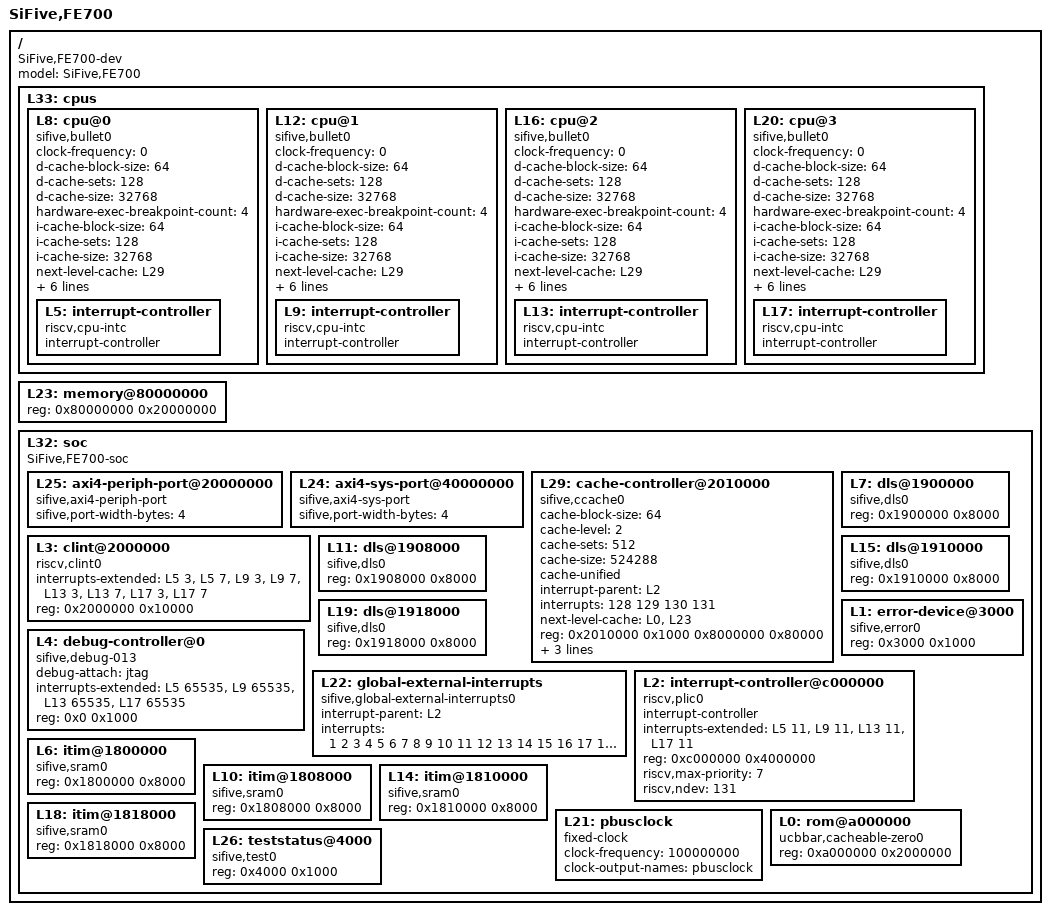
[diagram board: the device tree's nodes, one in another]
/dts-v1/;

/ {
	#address-cells = <1>;
	#size-cells = <1>;
	compatible = "SiFive,FE700-dev", "fe700-dev", "sifive-dev";
	model = "SiFive,FE700";
	L33: cpus {
		#address-cells = <1>;
		#size-cells = <0>;
		L8: cpu@0 {
			clock-frequency = <0>;
			compatible = "sifive,bullet0", "riscv";
			d-cache-block-size = <64>;
			d-cache-sets = <128>;
			d-cache-size = <32768>;
			device_type = "cpu";
			hardware-exec-breakpoint-count = <4>;
			i-cache-block-size = <64>;
			i-cache-sets = <128>;
			i-cache-size = <32768>;
			next-level-cache = <&L29>;
			reg = <0x0>;
			riscv,isa = "rv32imafc";
			riscv,pmpregions = <8>;
			sifive,dls = <&L7>;
			sifive,itim = <&L6>;
			status = "okay";
			timebase-frequency = <1000000>;
			L5: interrupt-controller {
				#interrupt-cells = <1>;
				compatible = "riscv,cpu-intc";
				interrupt-controller;
			};
		};
		L12: cpu@1 {
			clock-frequency = <0>;
			compatible = "sifive,bullet0", "riscv";
			d-cache-block-size = <64>;
			d-cache-sets = <128>;
			d-cache-size = <32768>;
			device_type = "cpu";
			hardware-exec-breakpoint-count = <4>;
			i-cache-block-size = <64>;
			i-cache-sets = <128>;
			i-cache-size = <32768>;
			next-level-cache = <&L29>;
			reg = <0x1>;
			riscv,isa = "rv32imafc";
			riscv,pmpregions = <8>;
			sifive,dls = <&L11>;
			sifive,itim = <&L10>;
			status = "okay";
			timebase-frequency = <1000000>;
			L9: interrupt-controller {
				#interrupt-cells = <1>;
				compatible = "riscv,cpu-intc";
				interrupt-controller;
			};
		};
		L16: cpu@2 {
			clock-frequency = <0>;
			compatible = "sifive,bullet0", "riscv";
			d-cache-block-size = <64>;
			d-cache-sets = <128>;
			d-cache-size = <32768>;
			device_type = "cpu";
			hardware-exec-breakpoint-count = <4>;
			i-cache-block-size = <64>;
			i-cache-sets = <128>;
			i-cache-size = <32768>;
			next-level-cache = <&L29>;
			reg = <0x2>;
			riscv,isa = "rv32imafc";
			riscv,pmpregions = <8>;
			sifive,dls = <&L15>;
			sifive,itim = <&L14>;
			status = "okay";
			timebase-frequency = <1000000>;
			L13: interrupt-controller {
				#interrupt-cells = <1>;
				compatible = "riscv,cpu-intc";
				interrupt-controller;
			};
		};
		L20: cpu@3 {
			clock-frequency = <0>;
			compatible = "sifive,bullet0", "riscv";
			d-cache-block-size = <64>;
			d-cache-sets = <128>;
			d-cache-size = <32768>;
			device_type = "cpu";
			hardware-exec-breakpoint-count = <4>;
			i-cache-block-size = <64>;
			i-cache-sets = <128>;
			i-cache-size = <32768>;
			next-level-cache = <&L29>;
			reg = <0x3>;
			riscv,isa = "rv32imafc";
			riscv,pmpregions = <8>;
			sifive,dls = <&L19>;
			sifive,itim = <&L18>;
			status = "okay";
			timebase-frequency = <1000000>;
			L17: interrupt-controller {
				#interrupt-cells = <1>;
				compatible = "riscv,cpu-intc";
				interrupt-controller;
			};
		};
	};
	L23: memory@80000000 {
		device_type = "memory";
		reg = <0x80000000 0x20000000>;
	};
	L32: soc {
		#address-cells = <1>;
		#size-cells = <1>;
		compatible = "SiFive,FE700-soc", "fe700-soc", "sifive-soc", "simple-bus";
		ranges;
		L25: axi4-periph-port@20000000 {
			#address-cells = <1>;
			#size-cells = <1>;
			compatible = "sifive,axi4-periph-port", "sifive,axi4-port", "sifive,periph-port", "simple-external-bus", "simple-bus";
			ranges = <0x20000000 0x20000000 0x20000000>;
			sifive,port-width-bytes = <4>;
		};
		L24: axi4-sys-port@40000000 {
			#address-cells = <1>;
			#size-cells = <1>;
			compatible = "sifive,axi4-sys-port", "sifive,axi4-port", "sifive,sys-port", "simple-external-bus", "simple-bus";
			ranges = <0x40000000 0x40000000 0x20000000>;
			sifive,port-width-bytes = <4>;
		};
		L29: cache-controller@2010000 {
			cache-block-size = <64>;
			cache-level = <2>;
			cache-sets = <512>;
			cache-size = <524288>;
			cache-unified;
			compatible = "sifive,ccache0", "cache";
			interrupt-parent = <&L2>;
			interrupts = <128 129 130 131>;
			next-level-cache = <&L0 &L23>;
			reg = <0x2010000 0x1000 0x8000000 0x80000>;
			reg-names = "control", "sideband";
			sifive,a-mshr-count = <6>;
			sifive,bank-count = <2>;
			sifive,ecc-granularity = <4>;
		};
		L3: clint@2000000 {
			compatible = "riscv,clint0";
			interrupts-extended = <&L5 3 &L5 7 &L9 3 &L9 7 &L13 3 &L13 7 &L17 3 &L17 7>;
			reg = <0x2000000 0x10000>;
			reg-names = "control";
		};
		L4: debug-controller@0 {
			compatible = "sifive,debug-013", "riscv,debug-013";
			debug-attach = "jtag";
			interrupts-extended = <&L5 65535 &L9 65535 &L13 65535 &L17 65535>;
			reg = <0x0 0x1000>;
			reg-names = "control";
		};
		L7: dls@1900000 {
			compatible = "sifive,dls0";
			reg = <0x1900000 0x8000>;
			reg-names = "mem";
		};
		L11: dls@1908000 {
			compatible = "sifive,dls0";
			reg = <0x1908000 0x8000>;
			reg-names = "mem";
		};
		L15: dls@1910000 {
			compatible = "sifive,dls0";
			reg = <0x1910000 0x8000>;
			reg-names = "mem";
		};
		L19: dls@1918000 {
			compatible = "sifive,dls0";
			reg = <0x1918000 0x8000>;
			reg-names = "mem";
		};
		L1: error-device@3000 {
			compatible = "sifive,error0";
			reg = <0x3000 0x1000>;
		};
		L22: global-external-interrupts {
			compatible = "sifive,global-external-interrupts0";
			interrupt-parent = <&L2>;
			interrupts = <1 2 3 4 5 6 7 8 9 10 11 12 13 14 15 16 17 18 19 20 21 22 23 24 25 26 27 28 29 30 31 32 33 34 35 36 37 38 39 40 41 42 43 44 45 46 47 48 49 50 51 52 53 54 55 56 57 58 59 60 61 62 63 64 65 66 67 68 69 70 71 72 73 74 75 76 77 78 79 80 81 82 83 84 85 86 87 88 89 90 91 92 93 94 95 96 97 98 99 100 101 102 103 104 105 106 107 108 109 110 111 112 113 114 115 116 117 118 119 120 121 122 123 124 125 126 127>;
		};
		L2: interrupt-controller@c000000 {
			#interrupt-cells = <1>;
			compatible = "riscv,plic0";
			interrupt-controller;
			interrupts-extended = <&L5 11 &L9 11 &L13 11 &L17 11>;
			reg = <0xc000000 0x4000000>;
			reg-names = "control";
			riscv,max-priority = <7>;
			riscv,ndev = <131>;
		};
		L6: itim@1800000 {
			compatible = "sifive,sram0";
			reg = <0x1800000 0x8000>;
			reg-names = "mem";
		};
		L10: itim@1808000 {
			compatible = "sifive,sram0";
			reg = <0x1808000 0x8000>;
			reg-names = "mem";
		};
		L14: itim@1810000 {
			compatible = "sifive,sram0";
			reg = <0x1810000 0x8000>;
			reg-names = "mem";
		};
		L18: itim@1818000 {
			compatible = "sifive,sram0";
			reg = <0x1818000 0x8000>;
			reg-names = "mem";
		};
		L21: pbusclock {
			#clock-cells = <0>;
			clock-frequency = <100000000>;
			clock-output-names = "pbusclock";
			compatible = "fixed-clock";
		};
		L0: rom@a000000 {
			compatible = "ucbbar,cacheable-zero0";
			reg = <0xa000000 0x2000000>;
		};
		L26: teststatus@4000 {
			compatible = "sifive,test0";
			reg = <0x4000 0x1000>;
			reg-names = "control";
		};
	};
};
